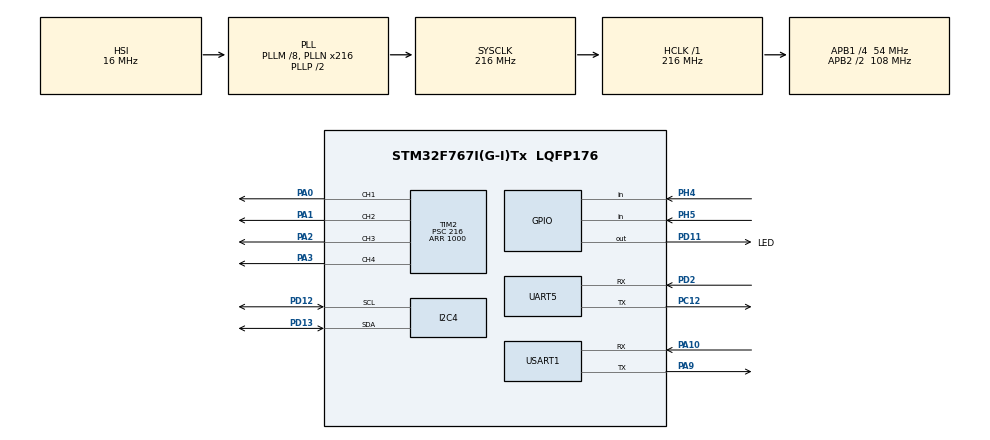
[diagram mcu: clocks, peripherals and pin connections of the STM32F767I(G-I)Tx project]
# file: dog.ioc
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Mcu.Family=STM32F7
RCC.CortexFreq_Value=216000000
PC12.Signal=UART5_TX
PA0/WKUP.Signal=S_TIM2_CH1_ETR
TIM2.Channel-PWM\ Generation2\ CH2=TIM_CHANNEL_2
PD11.PinState=GPIO_PIN_RESET
RCC.SYSCLKSource=RCC_SYSCLKSOURCE_PLLCLK
ProjectManager.StackSize=0x400
VP_FREERTOS_VS_CMSIS_V2.Mode=CMSIS_V2
PD13.Signal=I2C4_SDA
FREERTOS.configENABLE_FPU=1
PH5.Signal=GPIO_Input
I2C4.Timing=0x20404768
PH0/OSC_IN.Mode=HSE-External-Oscillator
PD11.GPIO_Label=LED
RCC.HCLKFreq_Value=216000000
RCC.APB2TimFreq_Value=216000000
PH1/OSC_OUT.Signal=RCC_OSC_OUT
RCC.AHBFreq_Value=216000000
RCC.HSE_VALUE=25000000
PH4.GPIO_PuPd=GPIO_PULLUP
PA14.Mode=Serial_Wire
VP_SYS_VS_tim1.Mode=TIM1
TIM2.Channel-PWM\ Generation1\ CH1=TIM_CHANNEL_1
PH1/OSC_OUT.Mode=HSE-External-Oscillator
FREERTOS.configTOTAL_HEAP_SIZE=36864
Mcu.Package=LQFP176
TIM2.Prescaler=216
NVIC.TimeBase=TIM1_UP_TIM10_IRQn
PD12.Signal=I2C4_SCL
NVIC.TimeBaseIP=TIM1
PA10.Signal=USART1_RX
RCC.APB2CLKDivider=RCC_HCLK_DIV2
RCC.APB1TimFreq_Value=108000000
PA3.Signal=S_TIM2_CH4
TIM2.Channel-PWM\ Generation4\ CH4=TIM_CHANNEL_4
CORTEX_M7.CPU_ICache=Enabled
FREERTOS.Tasks01=defaultTask,24,128,StartDefaultTask,Default,NULL,Dynamic,NULL,NULL
PA10.Mode=Asynchronous
RCC.APB1CLKDivider=RCC_HCLK_DIV4
USART1.VirtualMode-Asynchronous=VM_ASYNC
PA13.Signal=SYS_JTMS-SWDIO
SH.S_TIM2_CH2.0=TIM2_CH2,PWM Generation2 CH2
PA9.Mode=Asynchronous
PH4.Signal=GPIO_Input
ProjectManager.TargetToolchain=Makefile
PH5.GPIO_PuPd=GPIO_PULLUP
PA9.Signal=USART1_TX
PD13.Mode=I2C
RCC.USBFreq_Value=216000000
RCC.LSE_VALUE=32768
PA1.Signal=S_TIM2_CH2
PD2.Mode=Asynchronous
PC12.Mode=Asynchronous
board=custom
RCC.VCOOutputFreq_Value=432000000
PH0/OSC_IN.Signal=RCC_OSC_IN
RCC.APB2Freq_Value=108000000
SH.S_TIM2_CH3.0=TIM2_CH3,PWM Generation3 CH3
TIM2.Channel-PWM\ Generation3\ CH3=TIM_CHANNEL_3
TIM2.Period=1000
PA13.Mode=Serial_Wire
Mcu.Name=STM32F767I(G-I)Tx
PA2.Signal=S_TIM2_CH3
RCC.SYSCLKFreq_VALUE=216000000
PD12.Mode=I2C
USART1.AutoBaudRateEnableParam=UART_ADVFEATURE_AUTOBAUDRATE_DISABLE
PD11.Signal=GPIO_Output
SH.S_TIM2_CH1_ETR.0=TIM2_CH1,PWM Generation1 CH1
PA14.Signal=SYS_JTCK-SWCLK
ProjectManager.HeapSize=0x200
SH.S_TIM2_CH4.0=TIM2_CH4,PWM Generation4 CH4
NVIC.TIM1_UP_TIM10_IRQn=true\:0\:0\:false\:false\:true\:false\:false\:true
RCC.HSI_VALUE=16000000
NVIC.PriorityGroup=NVIC_PRIORITYGROUP_4
RCC.PLLM=8
RCC.PLLN=216
TIM2.AutoReloadPreload=TIM_AUTORELOAD_PRELOAD_ENABLE
CORTEX_M7.CPU_DCache=Enabled
PD2.Signal=UART5_RX
RCC.APB1Freq_Value=54000000

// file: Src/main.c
/* USER CODE BEGIN Header */
/**
  ******************************************************************************
  * @file           : main.c
  * @brief          : Main program body
  ******************************************************************************
  * @attention
  *
  * <h2><center>&copy; Copyright (c) 2020 STMicroelectronics.
  * All rights reserved.</center></h2>
  *
  * This software component is licensed by ST under BSD 3-Clause license,
  * the "License"; You may not use this file except in compliance with the
  * License. You may obtain a copy of the License at:
  *                        opensource.org/licenses/BSD-3-Clause
  *
  ******************************************************************************
  */
/* USER CODE END Header */

#include "main.h"
#include "cmsis_os.h"
#include "i2c.h"
#include "tim.h"
#include "usart.h"
#include "gpio.h"

void SystemClock_Config(void);
void MX_FREERTOS_Init(void);

int main(void)
{

  /* Enable I-Cache---------------------------------------------------------*/
  SCB_EnableICache();

  /* Enable D-Cache---------------------------------------------------------*/
  SCB_EnableDCache();

  /* MCU Configuration--------------------------------------------------------*/

  /* Reset of all peripherals, Initializes the Flash interface and the Systick. */
  HAL_Init();

  /* Configure the system clock */
  SystemClock_Config();

  /* Initialize all configured peripherals */
  MX_GPIO_Init();
  MX_I2C4_Init();
  MX_UART5_Init();
  MX_USART1_UART_Init();
  MX_TIM2_Init();

  /* Init scheduler */
  osKernelInitialize();  /* Call init function for freertos objects (in freertos.c) */
  MX_FREERTOS_Init();
  /* Start scheduler */
  osKernelStart();

  /* We should never get here as control is now taken by the scheduler */
  /* Infinite loop */
    while (1)
    {

    }
}

void SystemClock_Config(void)
{
  RCC_OscInitTypeDef RCC_OscInitStruct = {0};
  RCC_ClkInitTypeDef RCC_ClkInitStruct = {0};
  RCC_PeriphCLKInitTypeDef PeriphClkInitStruct = {0};

  /** Configure the main internal regulator output voltage
  */
  __HAL_RCC_PWR_CLK_ENABLE();
  __HAL_PWR_VOLTAGESCALING_CONFIG(PWR_REGULATOR_VOLTAGE_SCALE1);
  /** Initializes the CPU, AHB and APB busses clocks
  */
  RCC_OscInitStruct.OscillatorType = RCC_OSCILLATORTYPE_HSI;
  RCC_OscInitStruct.HSIState = RCC_HSI_ON;
  RCC_OscInitStruct.HSICalibrationValue = RCC_HSICALIBRATION_DEFAULT;
  RCC_OscInitStruct.PLL.PLLState = RCC_PLL_ON;
  RCC_OscInitStruct.PLL.PLLSource = RCC_PLLSOURCE_HSI;
  RCC_OscInitStruct.PLL.PLLM = 8;
  RCC_OscInitStruct.PLL.PLLN = 216;
  RCC_OscInitStruct.PLL.PLLP = RCC_PLLP_DIV2;
  RCC_OscInitStruct.PLL.PLLQ = 2;
  if (HAL_RCC_OscConfig(&RCC_OscInitStruct) != HAL_OK)
  {
    Error_Handler();
  }
  /** Activate the Over-Drive mode
  */
  if (HAL_PWREx_EnableOverDrive() != HAL_OK)
  {
    Error_Handler();
  }
  /** Initializes the CPU, AHB and APB busses clocks
  */
  RCC_ClkInitStruct.ClockType = RCC_CLOCKTYPE_HCLK|RCC_CLOCKTYPE_SYSCLK
                              |RCC_CLOCKTYPE_PCLK1|RCC_CLOCKTYPE_PCLK2;
  RCC_ClkInitStruct.SYSCLKSource = RCC_SYSCLKSOURCE_PLLCLK;
  RCC_ClkInitStruct.AHBCLKDivider = RCC_SYSCLK_DIV1;
  RCC_ClkInitStruct.APB1CLKDivider = RCC_HCLK_DIV4;
  RCC_ClkInitStruct.APB2CLKDivider = RCC_HCLK_DIV2;

  if (HAL_RCC_ClockConfig(&RCC_ClkInitStruct, FLASH_LATENCY_7) != HAL_OK)
  {
    Error_Handler();
  }
  PeriphClkInitStruct.PeriphClockSelection = RCC_PERIPHCLK_USART1|RCC_PERIPHCLK_UART5
                              |RCC_PERIPHCLK_I2C4;
  PeriphClkInitStruct.Usart1ClockSelection = RCC_USART1CLKSOURCE_PCLK2;
  PeriphClkInitStruct.Uart5ClockSelection = RCC_UART5CLKSOURCE_PCLK1;
  PeriphClkInitStruct.I2c4ClockSelection = RCC_I2C4CLKSOURCE_PCLK1;
  if (HAL_RCCEx_PeriphCLKConfig(&PeriphClkInitStruct) != HAL_OK)
  {
    Error_Handler();
  }
}

 /**
  * @brief  Period elapsed callback in non blocking mode
  * @note   This function is called  when TIM1 interrupt took place, inside
  * HAL_TIM_IRQHandler(). It makes a direct call to HAL_IncTick() to increment
  * a global variable "uwTick" used as application time base.
  * @param  htim : TIM handle
  * @retval None
  */
void HAL_TIM_PeriodElapsedCallback(TIM_HandleTypeDef *htim)
{
  if (htim->Instance == TIM1) {
    HAL_IncTick();
  }
}

void Error_Handler(void)
{
}

/************************ (C) COPYRIGHT STMicroelectronics *****END OF FILE****/

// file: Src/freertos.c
/* USER CODE BEGIN Header */
/**
  ******************************************************************************
  * File Name          : freertos.c
  * Description        : Code for freertos applications
  ******************************************************************************
  * @attention
  *
  * <h2><center>&copy; Copyright (c) 2020 STMicroelectronics.
  * All rights reserved.</center></h2>
  *
  * This software component is licensed by ST under Ultimate Liberty license
  * SLA0044, the "License"; You may not use this file except in compliance with
  * the License. You may obtain a copy of the License at:
  *                             www.st.com/SLA0044
  *
  ******************************************************************************
  */
/* USER CODE END Header */

#include "FreeRTOS.h"
#include "task.h"
#include "main.h"
#include "cmsis_os.h"

/* USER CODE BEGIN Includes */

#include "all_task_creat.h"
/* USER CODE END Includes */

/* Definitions for defaultTask */
osThreadId_t defaultTaskHandle;
const osThreadAttr_t defaultTask_attributes = {
  .name = "defaultTask",
  .priority = (osPriority_t) osPriorityNormal,
  .stack_size = 128 * 4
};

void StartDefaultTask(void *argument);

void MX_FREERTOS_Init(void); /* (MISRA C 2004 rule 8.1) */

void MX_FREERTOS_Init(void) {

  /* Create the thread(s) */
  /* creation of defaultTask */
  defaultTaskHandle = osThreadNew(StartDefaultTask, NULL, &defaultTask_attributes);

  /* USER CODE BEGIN RTOS_THREADS */
    /* add threads, ... */
    xAllTaskCreat();
  /* USER CODE END RTOS_THREADS */

}

void StartDefaultTask(void *argument)
{
    for (;;)
    {
        osDelay(1);
    }
}

/************************ (C) COPYRIGHT STMicroelectronics *****END OF FILE****/
